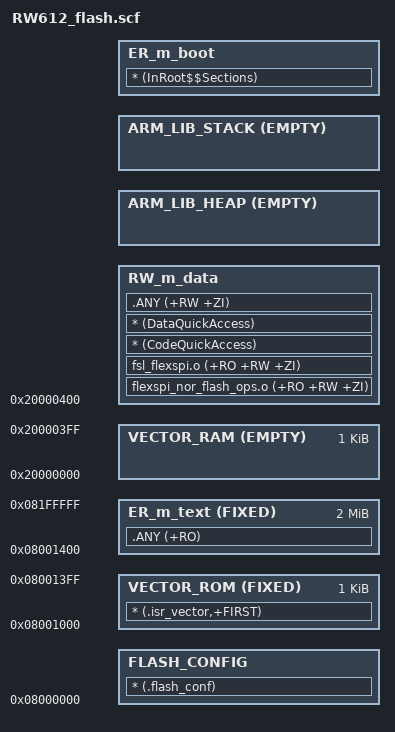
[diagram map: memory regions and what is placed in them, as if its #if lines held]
#!armclang --target=arm-arm-none-eabi -march=armv8-m.main -E -x c
/*
** ###################################################################
**     Processors:          RW612ETA2I
**                          RW612HNA2I
**                          RW612UKA2I
**
**     Compiler:            Keil ARM C/C++ Compiler
**     Reference manual:    RW61X User manual Rev. 0.95, June 2022
**     Version:             rev. 1.0, 2021-03-16
**     Build:               b231201
**
**     Abstract:
**         Linker file for the Keil ARM C/C++ Compiler
**
**     Copyright 2016 Freescale Semiconductor, Inc.
**     Copyright 2016-2023 NXP
**     SPDX-License-Identifier: BSD-3-Clause
**
**     http:                 www.nxp.com
**     mail:                 support@nxp.com
**
** ###################################################################
*/


/* Sizes */
#if (defined(__stack_size__))
  #define Stack_Size                   __stack_size__
#else
  #define Stack_Size                   0x0400
#endif

#if (defined(__heap_size__))
  #define Heap_Size                    __heap_size__
#else
  #define Heap_Size                    0x0400
#endif

#if (defined(__ram_vector_table__))
  #define __ram_vector_table_size__    0x00000400
#else
  #define __ram_vector_table_size__    0x00000000
#endif

#define  m_interrupts_start            0x08001000
#define  m_interrupts_size             0x00000400

#define  m_text_start                  0x08001400
#define  m_text_size                   0x001FEC00

#define m_interrupts_ram_start         0x20000000
#define m_interrupts_ram_size          __ram_vector_table_size__

/* Reserved [0x20123000, 0x2012FFFF] which is used by BootROM on PM3 wakeup. */
#define  m_data_start                  (m_interrupts_ram_start + m_interrupts_ram_size)
#define  m_data_size                   (0x00123000 - m_interrupts_ram_size)

#define  m_flash_start                 0x08000000

LR_m_flash_conf m_flash_start m_interrupts_start-m_flash_start {
  FLASH_CONFIG +0 { ; load address = execution address
    * (.flash_conf)
  }
}

LR_m_interrupts m_interrupts_start m_text_start+m_text_size-m_interrupts_start {
  VECTOR_ROM m_interrupts_start FIXED m_interrupts_size { ; load address = execution address
    * (.isr_vector,+FIRST)
  }

  ER_m_text m_text_start FIXED m_text_size { ; load address = execution address
    .ANY (+RO)
  }

#if (defined(__ram_vector_table__))
  VECTOR_RAM m_interrupts_ram_start EMPTY m_interrupts_ram_size {
  }
#else
  VECTOR_RAM m_interrupts_start EMPTY 0 {
  }
#endif

  RW_m_data m_data_start ALIGN 4 m_data_size-Stack_Size-Heap_Size { ; RW data
    /* Necessary to run flash routines from RAM */
    flexspi_nor_flash_ops.o (+RO +RW +ZI)
    fsl_flexspi.o (+RO +RW +ZI)
    * (CodeQuickAccess)
    * (DataQuickAccess)
    .ANY (+RW +ZI)
  }

  ARM_LIB_HEAP +0 EMPTY Heap_Size {    ; Heap region growing up
  }
  ARM_LIB_STACK m_data_start+m_data_size EMPTY -Stack_Size { ; Stack region growing down
  }
}

LR_m_boot +0 {
  ER_m_boot +0 { ; load address = execution address
    * (InRoot$$Sections)
  }
}
